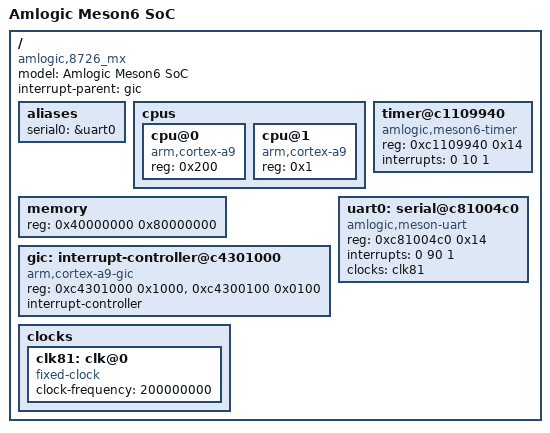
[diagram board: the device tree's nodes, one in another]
/*
 * Amlogic Meson6 DTS
 *
 * Copyright 2014 Carlo Caione <carlo@caione.org>
 *
 * This program is free software; you can redistribute it and/or modify it
 * under the terms of the GNU General Public License as published by the
 * Free Software Foundation; either version 2 of the License, or (at your
 * option) any later version.
 */

/dts-v1/;
/include/ "skeleton.dtsi"

/ {
	model = "Amlogic Meson6 SoC";
	compatible = "amlogic,8726_mx";

	interrupt-parent = <&gic>;

	aliases {
		serial0 = &uart0;
	};

	cpus {
		#address-cells = <1>;
		#size-cells = <0>;

		cpu@0 {
			device_type = "cpu";
			compatible = "arm,cortex-a9";
			reg = <0x200>;
        	};

        	cpu@1 {
			device_type = "cpu";
			compatible = "arm,cortex-a9";
			reg = <0x1>;
        	};
    	};

	memory {
		reg = <0x40000000 0x80000000>;
	};

	gic: interrupt-controller@c4301000 {
		compatible = "arm,cortex-a9-gic";
		reg = <0xc4301000 0x1000>,
		      <0xc4300100 0x0100>;
		interrupt-controller;
		#interrupt-cells = <3>;
	};

	timer@c1109940 {
		compatible = "amlogic,meson6-timer";
		reg = <0xc1109940 0x14>;
		interrupts = <0 10 1>;
	};

	clocks {
		#address-cells = <1>;

		clk81: clk@0 {
			#clock-cells = <0>;
			compatible = "fixed-clock";
			clock-frequency = <200000000>;
		};
	};

	uart0: serial@c81004c0 {
		compatible = "amlogic,meson-uart";
		reg = <0xc81004c0 0x14>;
		interrupts = <0 90 1>;
		clocks = <&clk81>;
	};
}; /* end of / */

